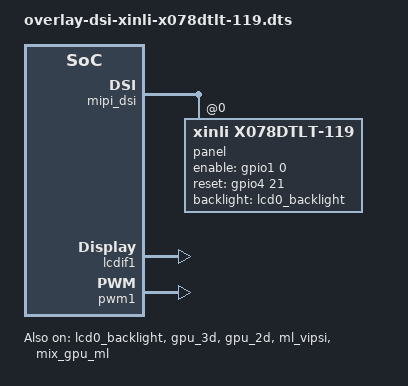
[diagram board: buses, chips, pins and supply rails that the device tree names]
/*
 * Copyright (C) 2022 Avnet Embedded GmbH
 *
 * This program is free software; you can redistribute it and/or
 * modify it under the terms of the GNU General Public License as
 * published by the Free Software Foundation version 2.
 *
 * This program is distributed "as is" WITHOUT ANY WARRANTY of any
 * kind, whether express or implied; without even the implied warranty
 * of MERCHANTABILITY or FITNESS FOR A PARTICULAR PURPOSE.  See the
 * GNU General Public License for more details.
 */


/dts-v1/;
/plugin/;

#include <dt-bindings/gpio/gpio.h>

/ {
	fragment@4200 {
		target = <&mipi_dsi>;
		__overlay__ {
			#address-cells = <1>;
			#size-cells = <0>;
			status = "okay";
			panel@0 {
				reg = <0>;
				pinctrl-names = "default";
				pinctrl-0 = <&pinctrl_lcd0_panel>;
				compatible = "xinli,x078dtlt-119";
				backlight = <&lcd0_backlight>;
				enable-gpios = <&gpio1 0 GPIO_ACTIVE_HIGH>;
				reset-gpios = <&gpio4 21 GPIO_ACTIVE_HIGH>;
				status = "okay";
			};
		};
	};

	fragment@4201 {
		target = <&lcdif1>;
		__overlay__ {
			status = "okay";
		};
	};

	fragment@4202 {
		target = <&pwm1>;
		__overlay__ {
			status = "okay";
		};
	};

	fragment@4203 {
		target = <&lcd0_backlight>;
		__overlay__ {
			status = "okay";
		};
	};

	fragment@4204 {
		target = <&gpu_3d>;
		__overlay__ {
			status = "okay";
		};
	};

	fragment@4205 {
		target = <&gpu_2d>;
		__overlay__ {
			status = "okay";
		};
	};

	fragment@4206 {
		target = <&ml_vipsi>;
		__overlay__ {
			status = "okay";
		};
	};

	fragment@4207 {
		target = <&mix_gpu_ml>;
		__overlay__ {
			status = "okay";
		};
	};
};
